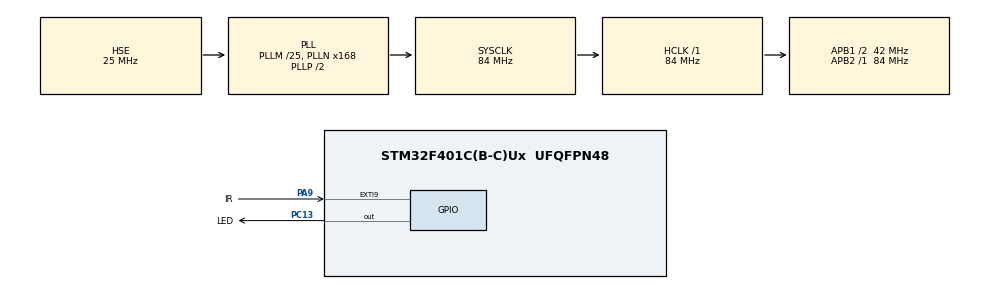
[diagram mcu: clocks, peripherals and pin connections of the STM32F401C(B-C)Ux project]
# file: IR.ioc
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Mcu.Family=STM32F4
Mcu.Name=STM32F401C(B-C)Ux
Mcu.Package=UFQFPN48
NVIC.EXTI9_5_IRQn=true\:0\:0\:false\:false\:true\:true\:true
NVIC.PriorityGroup=NVIC_PRIORITYGROUP_4
NVIC.TIM2_IRQn=true\:0\:0\:false\:false\:true\:true\:true
PA13.Mode=Serial_Wire
PA13.Signal=SYS_JTMS-SWDIO
PA14.Mode=Serial_Wire
PA14.Signal=SYS_JTCK-SWCLK
PA9.GPIO_Label=IR
PA9.GPIO_ModeDefaultEXTI=GPIO_MODE_IT_RISING_FALLING
PA9.Signal=GPXTI9
PC13-ANTI_TAMP.GPIO_Label=LED
PC13-ANTI_TAMP.Signal=GPIO_Output
PH0\ -\ OSC_IN.Mode=HSE-External-Oscillator
PH0\ -\ OSC_IN.Signal=RCC_OSC_IN
PH1\ -\ OSC_OUT.Mode=HSE-External-Oscillator
PH1\ -\ OSC_OUT.Signal=RCC_OSC_OUT
ProjectManager.HeapSize=0x200
ProjectManager.StackSize=0x400
ProjectManager.TargetToolchain=MDK-ARM V5.27
RCC.48MHZClocksFreq_Value=42000000
RCC.AHBFreq_Value=84000000
RCC.APB1CLKDivider=RCC_HCLK_DIV2
RCC.APB1Freq_Value=42000000
RCC.APB1TimFreq_Value=84000000
RCC.APB2Freq_Value=84000000
RCC.APB2TimFreq_Value=84000000
RCC.CortexFreq_Value=84000000
RCC.HCLKFreq_Value=84000000
RCC.HSE_VALUE=25000000
RCC.HSI_VALUE=16000000
RCC.LSE_VALUE=32768
RCC.PLLM=25
RCC.PLLN=168
RCC.PLLSourceVirtual=RCC_PLLSOURCE_HSE
RCC.SYSCLKFreq_VALUE=84000000
RCC.SYSCLKSource=RCC_SYSCLKSOURCE_PLLCLK
RCC.VCOOutputFreq_Value=168000000
TIM2.Period=10000 - 1
TIM2.Prescaler=84 - 1
VP_TIM2_VS_ClockSourceINT.Mode=Internal
board=custom

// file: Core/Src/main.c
/* USER CODE BEGIN Header */
/**
  ******************************************************************************
  * @file           : main.c
  * @brief          : Main program body
  ******************************************************************************
  * @attention
  *
  * <h2><center>&copy; Copyright (c) 2022 STMicroelectronics.
  * All rights reserved.</center></h2>
  *
  * This software component is licensed by ST under BSD 3-Clause license,
  * the "License"; You may not use this file except in compliance with the
  * License. You may obtain a copy of the License at:
  *                        opensource.org/licenses/BSD-3-Clause
  *
  ******************************************************************************
  */
/* USER CODE END Header */
#include "main.h"
#include "tim.h"
#include "gpio.h"

void SystemClock_Config(void);

/* USER CODE BEGIN 0 */

uint32_t ir_data = 0;
uint8_t ir_end = 1;
static uint8_t ir_cnt = 0;

/* USER CODE END 0 */

int main(void)
{

  /* MCU Configuration--------------------------------------------------------*/

  /* Reset of all peripherals, Initializes the Flash interface and the Systick. */
  HAL_Init();

  /* Configure the system clock */
  SystemClock_Config();

  /* Initialize all configured peripherals */
  MX_GPIO_Init();
  MX_TIM2_Init();
  /* USER CODE BEGIN 2 */

  HAL_GPIO_WritePin(LED_GPIO_Port, LED_Pin, GPIO_PIN_SET);

  /* USER CODE END 2 */

  /* Infinite loop */
  while (1)
  {

    /* USER CODE BEGIN 3 */

//    HAL_GPIO_TogglePin(LED_GPIO_Port, LED_Pin);

//    HAL_Delay(200);
  }
  /* USER CODE END 3 */
}

void SystemClock_Config(void)
{
  RCC_OscInitTypeDef RCC_OscInitStruct = {0};
  RCC_ClkInitTypeDef RCC_ClkInitStruct = {0};

  /** Configure the main internal regulator output voltage
  */
  __HAL_RCC_PWR_CLK_ENABLE();
  __HAL_PWR_VOLTAGESCALING_CONFIG(PWR_REGULATOR_VOLTAGE_SCALE2);
  /** Initializes the RCC Oscillators according to the specified parameters
  * in the RCC_OscInitTypeDef structure.
  */
  RCC_OscInitStruct.OscillatorType = RCC_OSCILLATORTYPE_HSE;
  RCC_OscInitStruct.HSEState = RCC_HSE_ON;
  RCC_OscInitStruct.PLL.PLLState = RCC_PLL_ON;
  RCC_OscInitStruct.PLL.PLLSource = RCC_PLLSOURCE_HSE;
  RCC_OscInitStruct.PLL.PLLM = 25;
  RCC_OscInitStruct.PLL.PLLN = 168;
  RCC_OscInitStruct.PLL.PLLP = RCC_PLLP_DIV2;
  RCC_OscInitStruct.PLL.PLLQ = 4;
  if (HAL_RCC_OscConfig(&RCC_OscInitStruct) != HAL_OK)
  {
    Error_Handler();
  }
  /** Initializes the CPU, AHB and APB buses clocks
  */
  RCC_ClkInitStruct.ClockType = RCC_CLOCKTYPE_HCLK|RCC_CLOCKTYPE_SYSCLK
                              |RCC_CLOCKTYPE_PCLK1|RCC_CLOCKTYPE_PCLK2;
  RCC_ClkInitStruct.SYSCLKSource = RCC_SYSCLKSOURCE_PLLCLK;
  RCC_ClkInitStruct.AHBCLKDivider = RCC_SYSCLK_DIV1;
  RCC_ClkInitStruct.APB1CLKDivider = RCC_HCLK_DIV2;
  RCC_ClkInitStruct.APB2CLKDivider = RCC_HCLK_DIV1;

  if (HAL_RCC_ClockConfig(&RCC_ClkInitStruct, FLASH_LATENCY_2) != HAL_OK)
  {
    Error_Handler();
  }
}

/* USER CODE BEGIN 4 */

void HAL_TIM_PeriodElapsedCallback(TIM_HandleTypeDef *htim) {
  if(htim == &htim2) {
    HAL_TIM_Base_Stop_IT(&htim2);

    ir_end = 1;
  }
}

void HAL_GPIO_EXTI_Callback(uint16_t GPIO_Pin) {
  if (GPIO_Pin == IR_Pin) {
    HAL_NVIC_DisableIRQ(EXTI9_5_IRQn);

    if(HAL_GPIO_ReadPin(IR_GPIO_Port, IR_Pin)) {
      // timer start
      __HAL_TIM_SET_COUNTER(&htim2, 0);

      HAL_GPIO_WritePin(LED_GPIO_Port, LED_Pin, GPIO_PIN_SET);
    } else {
      uint16_t period = __HAL_TIM_GetCounter(&htim2);

      __HAL_TIM_SET_COUNTER(&htim2, 0);
      HAL_TIM_Base_Start_IT(&htim2);

      if(ir_end == 0) {
        if(period < 1125) {
          // 5
          HAL_GPIO_WritePin(LED_GPIO_Port, LED_Pin, GPIO_PIN_RESET);

          ir_data <<= 1;
          ir_data |= 0x00;

          ir_cnt++;
        } else if(period < 6750) {
          if(period < 3094 && period < 2000) {
            // 55
            HAL_GPIO_WritePin(LED_GPIO_Port, LED_Pin, GPIO_PIN_RESET);

            ir_data <<= 1;
            ir_data |= 0x01;

            ir_cnt++;
          } else if(period > 3904) {
            ir_data = 0;
            ir_cnt = 0;
          } else {
            // repeat
          }
        }
      }

      ir_end = 0;
    }

    HAL_NVIC_EnableIRQ(EXTI9_5_IRQn);
    __HAL_GPIO_EXTI_CLEAR_IT(GPIO_Pin);
  }
}

/* USER CODE END 4 */

void Error_Handler(void)
{
}

/************************ (C) COPYRIGHT STMicroelectronics *****END OF FILE****/
